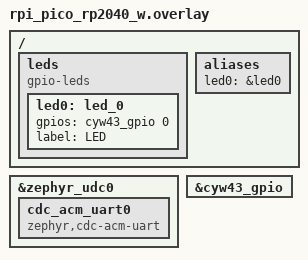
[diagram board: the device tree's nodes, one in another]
&zephyr_udc0 {
	cdc_acm_uart0: cdc_acm_uart0 {
		compatible = "zephyr,cdc-acm-uart";
	};
};

&cyw43_gpio {
	status = "okay";
};

/ {
	leds {
		compatible = "gpio-leds";

		led0: led_0 {
			gpios = <&cyw43_gpio 0 GPIO_ACTIVE_HIGH>;
			label = "LED";
		};
	};

	aliases {
		led0 = &led0;
	};
};

